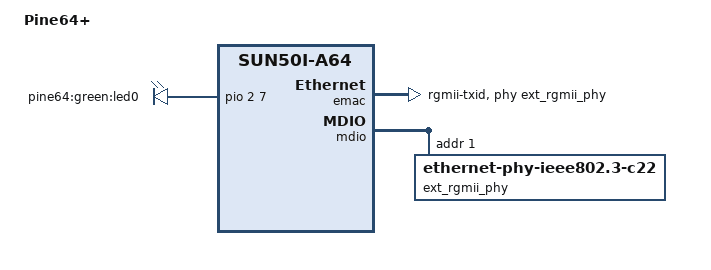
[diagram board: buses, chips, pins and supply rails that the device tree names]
// SPDX-License-Identifier: (GPL-2.0+ OR MIT)
// Copyright (c) 2016 ARM Ltd.

#include "sun50i-a64-pine64.dts"

/ {
	model = "Pine64+";
	compatible = "pine64,pine64-plus", "allwinner,sun50i-a64";

	/* TODO: Camera, touchscreen, etc. */

	leds {
		compatible = "gpio-leds";
		led0 {
			label = "pine64:green:led0";
			gpios = <&pio 2 7 GPIO_ACTIVE_HIGH>; /* PC7 / GPIO 17 */
			linux,default-trigger = "heartbeat";
			default-state = "off";
			status = "okay";
		};
	};
};

&emac {
	pinctrl-names = "default";
	pinctrl-0 = <&rgmii_pins>;
	phy-mode = "rgmii-txid";
	phy-handle = <&ext_rgmii_phy>;
	status = "okay";
};

&mdio {
	ext_rgmii_phy: ethernet-phy@1 {
		compatible = "ethernet-phy-ieee802.3-c22";
		reg = <1>;
	};
};

&reg_dc1sw {
	/*
	 * Ethernet PHY needs 30ms to properly power up and some more
	 * to initialize. 100ms should be plenty of time to finish
	 * whole process.
	 */
	regulator-enable-ramp-delay = <100000>;
};
